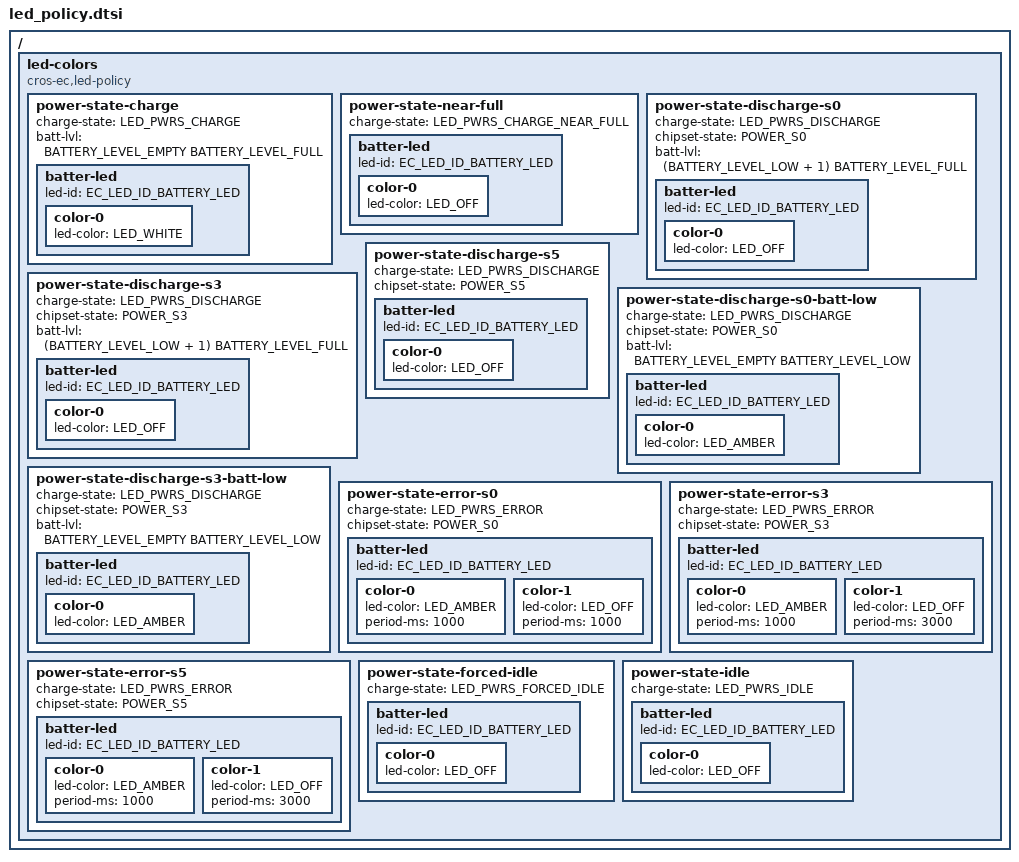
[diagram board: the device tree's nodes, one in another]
#include <dt-bindings/battery.h>

/ {
	led-colors {
		compatible = "cros-ec,led-policy";

		power-state-charge {
			charge-state = "LED_PWRS_CHARGE";
			batt-lvl = <BATTERY_LEVEL_EMPTY
						BATTERY_LEVEL_FULL>;

			batter-led {
				led-id = "EC_LED_ID_BATTERY_LED";

				color-0 {
					led-color = "LED_WHITE";
				};
			};
		};

		power-state-near-full {
			charge-state = "LED_PWRS_CHARGE_NEAR_FULL";

			batter-led {
				led-id = "EC_LED_ID_BATTERY_LED";

				color-0 {
					led-color = "LED_OFF";
				};
			};
		};

		power-state-discharge-s0 {
			charge-state = "LED_PWRS_DISCHARGE";
			chipset-state = "POWER_S0";
			batt-lvl = <(BATTERY_LEVEL_LOW + 1) BATTERY_LEVEL_FULL>;

			batter-led {
				led-id = "EC_LED_ID_BATTERY_LED";

				color-0 {
					led-color = "LED_OFF";
				};
			};
		};

		power-state-discharge-s3 {
			charge-state = "LED_PWRS_DISCHARGE";
			chipset-state = "POWER_S3";
			batt-lvl = <(BATTERY_LEVEL_LOW + 1) BATTERY_LEVEL_FULL>;

			batter-led {
				led-id = "EC_LED_ID_BATTERY_LED";

				color-0 {
					led-color = "LED_OFF";
				};
			};
		};

		power-state-discharge-s5 {
			charge-state = "LED_PWRS_DISCHARGE";
			chipset-state = "POWER_S5";

			batter-led {
				led-id = "EC_LED_ID_BATTERY_LED";

				color-0 {
					led-color = "LED_OFF";
				};
			};
		};

		power-state-discharge-s0-batt-low {
			charge-state = "LED_PWRS_DISCHARGE";
			chipset-state = "POWER_S0";
			batt-lvl = <BATTERY_LEVEL_EMPTY BATTERY_LEVEL_LOW>;

			batter-led {
				led-id = "EC_LED_ID_BATTERY_LED";

				color-0 {
					led-color = "LED_AMBER";
				};
			};
		};

		power-state-discharge-s3-batt-low {
			charge-state = "LED_PWRS_DISCHARGE";
			chipset-state = "POWER_S3";
			batt-lvl = <BATTERY_LEVEL_EMPTY BATTERY_LEVEL_LOW>;

			batter-led {
				led-id = "EC_LED_ID_BATTERY_LED";

				color-0 {
					led-color = "LED_AMBER";
				};
			};
		};

		power-state-error-s0 {
			charge-state = "LED_PWRS_ERROR";
			chipset-state = "POWER_S0";

			batter-led {
				led-id = "EC_LED_ID_BATTERY_LED";
				/* Amber 1 sec, off 1 sec */
				color-0 {
					led-color = "LED_AMBER";
					period-ms = <1000>;
				};
				color-1 {
					led-color = "LED_OFF";
					period-ms = <1000>;
				};
			};
		};

		power-state-error-s3 {
			charge-state = "LED_PWRS_ERROR";
			chipset-state = "POWER_S3";

			batter-led {
				led-id = "EC_LED_ID_BATTERY_LED";
				/* Amber 1 sec, off 3 sec */
				color-0 {
					led-color = "LED_AMBER";
					period-ms = <1000>;
				};
				color-1 {
					led-color = "LED_OFF";
					period-ms = <3000>;
				};
			};
		};

		power-state-error-s5 {
			charge-state = "LED_PWRS_ERROR";
			chipset-state = "POWER_S5";

			batter-led {
				led-id = "EC_LED_ID_BATTERY_LED";
				/* Amber 1 sec, off 3 sec */
				color-0 {
					led-color = "LED_AMBER";
					period-ms = <1000>;
				};
				color-1 {
					led-color = "LED_OFF";
					period-ms = <3000>;
				};
			};
		};

		power-state-forced-idle {
			charge-state = "LED_PWRS_FORCED_IDLE";

			batter-led {
				led-id = "EC_LED_ID_BATTERY_LED";
				color-0 {
					led-color = "LED_OFF";
				};
			};
		};

		power-state-idle {
			charge-state = "LED_PWRS_IDLE";

			batter-led {
				led-id = "EC_LED_ID_BATTERY_LED";
				color-0 {
					led-color = "LED_OFF";
				};
			};
		};
	};
};
